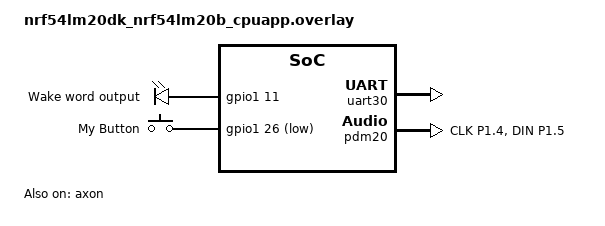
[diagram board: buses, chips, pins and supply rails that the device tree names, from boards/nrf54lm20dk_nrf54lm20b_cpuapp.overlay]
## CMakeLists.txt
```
#
# Copyright (c) 2026 Nordic Semiconductor ASA
#
# SPDX-License-Identifier: LicenseRef-Nordic-5-Clause
#

cmake_minimum_required(VERSION 3.20.0)

find_package(Zephyr REQUIRED HINTS $ENV{ZEPHYR_BASE})
project(ww_kws)

target_sources(app PRIVATE
  src/main.c

  src/control_output.c
  src/dmic.c
  src/leds.c

  src/ww/wakeword.c
  src/ww/nrf_edgeai_generated/nrf_edgeai_user_model.c

  src/kws/kws.c
  src/kws/nrf_edgeai_generated/nrf_edgeai_user_model.c

  src/dispenser.c
  src/button.c
)
```

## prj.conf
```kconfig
#
# Copyright (c) 2026 Nordic Semiconductor
#
# SPDX-License-Identifier: LicenseRef-Nordic-5-Clause
#

# nRF Edge AI
CONFIG_NRF_EDGEAI=y

# nRF Edge AI dependencies
CONFIG_NRF_AXON=y
CONFIG_NEWLIB_LIBC=y
CONFIG_FPU=y

# Size of interlayer buffer to fit model
CONFIG_NRF_AXON_INTERLAYER_BUFFER_SIZE=6656

# Size of psum buffer to fit model
CONFIG_NRF_AXON_PSUM_BUFFER_SIZE=0

# Enable sensor, button and LED libraries
CONFIG_GPIO=y
CONFIG_AUDIO=y
CONFIG_AUDIO_DMIC=y

# Enable logging and assert
CONFIG_LOG=y
CONFIG_CONSOLE=y
CONFIG_SERIAL=y
CONFIG_ASSERT=y

CONFIG_UART_ASYNC_API=y

#Only wake word
CONFIG_APP_MODE_WW_ONLY=y

#Power management
CONFIG_PM=y
```

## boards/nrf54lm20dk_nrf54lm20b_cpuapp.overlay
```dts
/*
 * Copyright (c) 2026 Nordic Semiconductor ASA
 *
 * SPDX-License-Identifier: LicenseRef-Nordic-5-Clause
 */

/ {
	chosen {
		ncs,control-output-uart = &uart30;
	};

	aliases {
        ww-out = &ww_pin;
		my-button = &button_pin;
    };
	ww_output {
		compatible = "gpio-leds"; // Reuse the gpio-leds compatible to ensure the system understands this is a GPIO output
    	ww_pin: ww_pin {
			gpios = <&gpio1 11 GPIO_ACTIVE_HIGH>; 
			label = "Wake word output";
		};
    };
	button_input {
		compatible = "gpio-keys"; // Reuse the gpio-keys compatible to ensure the system understands this is a GPIO input
		button_pin: button_pin {
			gpios = <&gpio1 26 GPIO_ACTIVE_LOW>; 
			label = "My Button";
		};
	};
};

&uart30 {
	status = "okay";
};

&pinctrl {
	pdm20_default_alt: pdm20_default_alt {
		group1 {
			psels = <NRF_PSEL(PDM_CLK, 1, 4)>,
				<NRF_PSEL(PDM_DIN, 1, 5)>;
		};
	};
};

&gpio1 {
    status = "okay";
};

dmic_dev: &pdm20 {
	status = "okay";
	pinctrl-0 = <&pdm20_default_alt>;
	pinctrl-names = "default";
	clock-source = "PCLK32M";
};

&axon {
	status = "okay";
};
```

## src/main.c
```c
/*
 * Copyright (c) 2026 Nordic Semiconductor ASA
 *
 * SPDX-License-Identifier: LicenseRef-Nordic-5-Clause
 */

#include <stddef.h>
#include <stdint.h>

#include <zephyr/audio/dmic.h>
#include <zephyr/device.h>
#include <zephyr/devicetree.h>
#include <zephyr/logging/log.h>
#include <zephyr/drivers/gpio.h>

#include "control_output.h"
#include "dmic.h"
#include "kws/kws.h"
#include "leds.h"
#include "ww/wakeword.h"
#include "button.h"
#include "dispenser.h"

LOG_MODULE_REGISTER(main);

#define DMIC_READ_TIMEOUT 100

static const struct device *const dmic_dev = DEVICE_DT_GET(DT_NODELABEL(dmic_dev));

static int ww_loop(void)
{
	int err;
	void *audio_buffer;
	size_t audio_buffer_size;
	bool ww_detected;

	ww_reset();

	print_control_output((struct control_message){CONTROL_MESSAGE_WAITING_WW});

	while (true) {
		err = dmic_read(dmic_dev, 0, &audio_buffer, &audio_buffer_size, DMIC_READ_TIMEOUT);
		if (err < 0) {
			LOG_ERR("Failed to read from DMIC (err %d)", err);
			return err;
		}

		err = ww_process(audio_buffer, DMIC_SAMPLES_IN_BLOCK, &ww_detected);
		if (err == -EBUSY) {
			/* More data is needed. */
			continue;
		} else if (err < 0) {
			LOG_ERR("Wakeword detection failed (err %d)", err);
			return err;
		}

		if (ww_detected) {
			leds_blink_led0();
			dispenser_dispense();
			print_control_output((struct control_message){CONTROL_MESSAGE_WW_DETECTED});
			
			if (IS_ENABLED(CONFIG_APP_MODE_WW_ONLY)) {
				leds_blink_led0();
			} else {
				return 0;
			}
		}
	}

	return 0;
}

static int kws_loop(void)
{
	int err;
	void *audio_buffer;
	size_t audio_buffer_size;
	struct kws_prediction prediction;

	uint32_t spotting_timeout = k_uptime_get_32() + CONFIG_KWS_PERIOD_MS;

	kws_reset();

	print_control_output((struct control_message){.type = CONTROL_MESSAGE_WAITING_KW});

	while (IS_ENABLED(CONFIG_APP_MODE_KWS_ONLY) || spotting_timeout > k_uptime_get_32()) {
		err = dmic_read(dmic_dev, 0, &audio_buffer, &audio_buffer_size, DMIC_READ_TIMEOUT);
		if (err < 0) {
			LOG_ERR("Failed to read from DMIC (err %d)", err);
			return err;
		}

		err = kws_process(audio_buffer, DMIC_SAMPLES_IN_BLOCK, &prediction);
		if (err == -EBUSY) {
			/* More data is needed. */
			continue;
		} else if (err) {
			LOG_ERR("Keyword spotting failed (err %d)", err);
			return err;
		}

		if (prediction.valid) {
			leds_blink_led1();
			spotting_timeout = k_uptime_get_32() + CONFIG_KWS_PERIOD_MS;
			print_control_output(
				(struct control_message){.type = CONTROL_MESSAGE_KW_SPOTTED,
							 .kw_class = prediction.class,
							 .name = prediction.name});
		}
	}

	print_control_output((struct control_message){.type = CONTROL_MESSAGE_TIMEOUT_KWS});

	return 0;
}

int main(void)
{
	int err;

	err = dmic_init();
	if (err) {
		return err;
	}

	err = leds_init();
	if (err) {
		return err;
	}

	err = control_output_init();
	if (err) {
		return err;
	}

	err = ww_init();
	if (err) {
		return err;
	}

	err = kws_init();
	if (err) {
		return err;
	}

	err = dispenser_init();
	if (err) {
		return err;
	}

	err = button_init();
	if (err) {
		return err;
	}
	button_setup_interrupt();
	
	LOG_INF("Initialization completed, check output on VCOM0");

	err = dmic_trigger(dmic_dev, DMIC_TRIGGER_START);
	if (err < 0) {
		LOG_ERR("Failed to start DMIC (err %d)", err);
		return err;
	}

	while (true) {
		if (IS_ENABLED(CONFIG_APP_MODE_WW_GATED_KWS) ||
		    IS_ENABLED(CONFIG_APP_MODE_WW_ONLY)) {
			err = ww_loop();
			if (err) {
				return err;
			}
		}

		if (IS_ENABLED(CONFIG_APP_MODE_WW_GATED_KWS)) {
			leds_on_led0();
		}

		if (IS_ENABLED(CONFIG_APP_MODE_WW_GATED_KWS) ||
		    IS_ENABLED(CONFIG_APP_MODE_KWS_ONLY)) {
			err = kws_loop();
			if (err) {
				return err;
			}
		}

		if (IS_ENABLED(CONFIG_APP_MODE_WW_GATED_KWS)) {
			leds_off_led0();
		}
	}

	return 0;
}
```

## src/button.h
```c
#ifndef __BUTTON_H__
#define __BUTTON_H__

#ifdef __cplusplus
extern "C" {
#endif /* __cplusplus */

int button_init(void);

void button_pressed(const struct device *dev, struct gpio_callback *cb, uint32_t pins);

void button_setup_interrupt(void);

#ifdef __cplusplus
}
#endif /* __cplusplus */

#endif /* __BUTTON_H__ */
```

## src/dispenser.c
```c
#include <zephyr/kernel.h>
#include <zephyr/drivers/gpio.h>
#include <zephyr/device.h>
#include <zephyr/devicetree.h>

#include "dispenser.h"

#define DISPENSE_TIME K_SECONDS(2)

static const struct gpio_dt_spec dispenser = GPIO_DT_SPEC_GET(DT_ALIAS(ww_out), gpios);

static void dispense_timer_expiry(struct k_timer *timer);
static K_TIMER_DEFINE(dispense_timer, dispense_timer_expiry, NULL);

int dispenser_init(void)
{
	if (!gpio_is_ready_dt(&dispenser)) {
        return -ENODEV;
    }
    gpio_pin_configure_dt(&dispenser, GPIO_OUTPUT_INACTIVE);
    return 0;
}

void dispenser_dispense(void)
{
    gpio_pin_set_dt(&dispenser, 1);
    k_timer_user_data_set(&dispense_timer, (void *)&dispenser);
    k_timer_start(&dispense_timer, DISPENSE_TIME, K_NO_WAIT);
}

static void dispense_timer_expiry(struct k_timer *timer)
{
    const struct gpio_dt_spec *dispenser = k_timer_user_data_get(timer);
    gpio_pin_set_dt(dispenser, 0);
}
```
